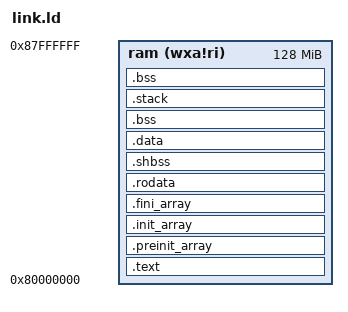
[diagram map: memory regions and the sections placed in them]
OUTPUT_ARCH( "riscv" )

ENTRY( _start )

MEMORY
{
  ram   (wxa!ri) : ORIGIN = 0x80000000, LENGTH = 128M
}

_stack_start = ORIGIN(ram) + LENGTH(ram);
_min_heap = 0x4000;
_min_stack = 0x4000;

_heap_start    = _bss_end;
_heap_end      = _stack_start;


SECTIONS
{
    .text : {
        . = ALIGN(4);
        _stext = .;
        *(.text.init) *(.text .text.*)
        _etext  =  .;
        __CTOR_LIST__ = .;
        LONG((__CTOR_END__ - __CTOR_LIST__) / 4 - 2)
        *(.ctors)
        LONG(0)
        __CTOR_END__ = .;
        __DTOR_LIST__ = .;
        LONG((__DTOR_END__ - __DTOR_LIST__) / 4 - 2)
        *(.dtors)
        LONG(0)
        __DTOR_END__ = .;
        *(.lit)
        *(.shdata)
        _endtext = .;
    }  > ram

    /*--------------------------------------------------------------------*/
    /* Global constructor/destructor segement                             */
    /*--------------------------------------------------------------------*/

    .preinit_array     :
    {
      PROVIDE_HIDDEN (__preinit_array_start = .);
      KEEP (*(.preinit_array))
      PROVIDE_HIDDEN (__preinit_array_end = .);
    } > ram

    .init_array     :
    {
      PROVIDE_HIDDEN (__init_array_start = .);
      KEEP (*(SORT(.init_array.*)))
      KEEP (*(.init_array ))
      PROVIDE_HIDDEN (__init_array_end = .);
    } > ram

    .fini_array     :
    {
      PROVIDE_HIDDEN (__fini_array_start = .);
      KEEP (*(SORT(.fini_array.*)))
      KEEP (*(.fini_array ))
      PROVIDE_HIDDEN (__fini_array_end = .);
    } > ram

    .rodata : {
        . = ALIGN(4);
        *(.rodata);
        *(.rodata.*)
        *(.srodata)
        *(.srodata.*)
    } > ram

    .shbss :
    {
        . = ALIGN(4);
        *(.shbss)
    } > ram

    .data : {
        . = ALIGN(4);
        sdata  =  .;
        _sdata  =  .;
        *(.data);
        *(.data.*)
        *(.sdata2.*)
        edata  =  .;
        _edata  =  .;
    } > ram

    .bss :
    {
        . = ALIGN(4);
        _bss_start = .;
        *(.bss)
        *(.bss.*)
        *(.sbss)
        *(.sbss.*)
        *(COMMON)
        _bss_end = .;
    } > ram

    _stack_addptr = ORIGIN(ram) + LENGTH(ram) - _bss_end - _min_stack;

    /* do not place anything after this address, because the heap starts here! */

    /* ensure there is enough room for stack */
    .stack (NOLOAD): {
        . = ALIGN(4);
        . = . + _min_heap;
        . = . + _min_stack;
        . = ALIGN(4);
    } > ram

    /* no data in the elf file the stack ram is included */
    .stab  0 (NOLOAD) :
    {
        [ .stab ]
    }

    .stabstr  0 (NOLOAD) :
    {
        [ .stabstr ]
    }

    .bss :
    {
        . = ALIGN(4);
        _end = .;
    } > ram
}
